# STM32F103xB register map
File version: 1.0
Registers are 32-bit, read-write, reset 0x0 unless marked. A register's access mark holds for its fields unless they carry their own. Offsets are from the block's base; [hi:lo] are bit positions; {n}, {i} and the like mark numbered series; 'fields as' and 'values as' point back to an identical list.

## BKP — Backup Registers
Base 0x40006C00
{0x0+4i} DR{i} (i=1..10)
  [15:0] D — Backup data
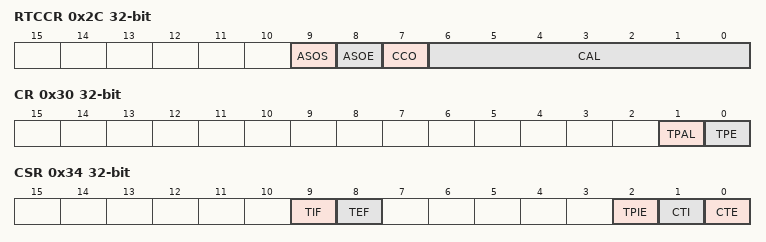
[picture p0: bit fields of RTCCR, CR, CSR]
0x2C RTCCR
  [9] ASOS — Alarm or Second Output Selection
  [8] ASOE — Alarm or Second Output Enable
  [7] CCO — Calibration Clock Output
  [6:0] CAL — Calibration value
0x30 CR
  [1] TPAL — TAMPER pin active level
    1=LOW (A high level on the TAMPER pin resets all data backup registers (if TPE bit is set)); 0=HIGH (A low level on the TAMPER pin resets all data backup registers (if TPE bit is set))
  [0] TPE — TAMPER pin enable
0x34 CSR
  [9] TIF — Tamper Interrupt Flag
  [8] TEF — Tamper Event Flag
  [2] TPIE — TAMPER Pin interrupt enable
  [1] CTI — Clear Tamper Interrupt
  [0] CTE — Clear Tamper event

## PWR — Power Control
Base 0x40007000
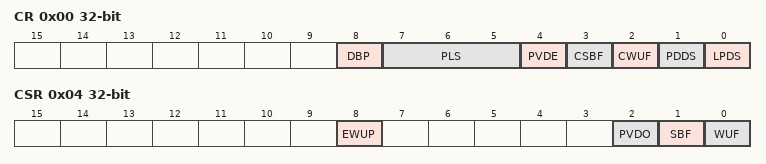
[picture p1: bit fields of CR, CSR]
0x00 CR
  [8] DBP — Disable Backup Domain write protection
  [7:5] PLS — PLS[2:0] bits (PVD Level Selection)
    0=PVDLEVEL_0 (Voltage threshold detected by PVD 2.2 V); 1=PVDLEVEL_1 (Voltage threshold detected by PVD 2.3 V); 2=PVDLEVEL_2 (Voltage threshold detected by PVD 2.4 V); 3=PVDLEVEL_3 (Voltage threshold detected by PVD 2.5 V); 4=PVDLEVEL_4 (Voltage threshold detected by PVD 2.6 V); 5=PVDLEVEL_5 (Voltage threshold detected by PVD 2.7 V); 6=PVDLEVEL_6 (Voltage threshold detected by PVD 2.8 V); 7=PVDLEVEL_7 (Voltage threshold detected by PVD 2.9 V)
  [4] PVDE — Power Voltage Detector Enable
  [3] CSBF — Clear Standby Flag
  [2] CWUF — Clear Wakeup Flag
  [1] PDDS — Power Down Deepsleep
  [0] LPDS — Low-Power Deepsleep
    0=MAIN (Voltage Regulator in main mode during deepsleep mode); 1=LOW_POWER (Voltage Regulator in low-power mode during deepsleep mode)
0x04 CSR
  [8] EWUP — Enable WKUP pin
  [2] PVDO — PVD Output
  [1] SBF — Standby Flag
  [0] WUF — Wakeup Flag

## AFIO — Alternate Function I/O
Base 0x40010000
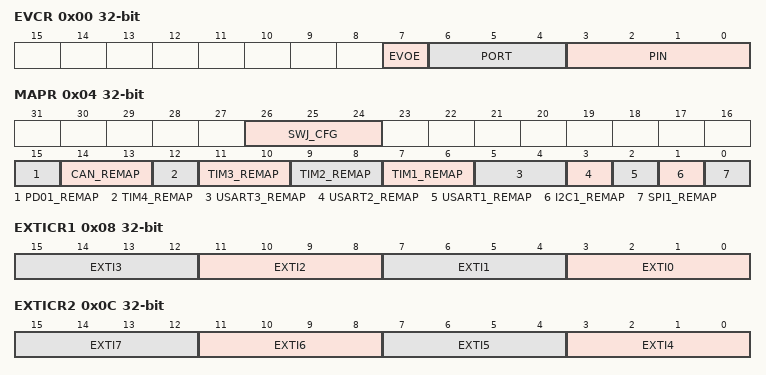
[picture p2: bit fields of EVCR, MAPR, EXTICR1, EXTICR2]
0x00 EVCR
  [7] EVOE — Event Output Enable
  [6:4] PORT — PORT[2:0] bits (Port selection)
  [3:0] PIN — PIN[3:0] bits (Pin selection)
0x04 MAPR
  [26:24] SWJ_CFG — SWJ_CFG[2:0] bits (Serial Wire JTAG configuration)
  [15] PD01_REMAP — Port D0/Port D1 mapping on OSC_IN/OSC_OUT
  [14:13] CAN_REMAP — CAN_REMAP[1:0] bits (CAN Alternate function remapping)
  [12] TIM4_REMAP — TIM4_REMAP bit (TIM4 remapping)
  [11:10] TIM3_REMAP — TIM3_REMAP[1:0] bits (TIM3 remapping)
  [9:8] TIM2_REMAP — TIM2_REMAP[1:0] bits (TIM2 remapping)
  [7:6] TIM1_REMAP — TIM1_REMAP[1:0] bits (TIM1 remapping)
  [5:4] USART3_REMAP — USART3_REMAP[1:0] bits (USART3 remapping)
  [3] USART2_REMAP — USART2 remapping
  [2] USART1_REMAP — USART1 remapping
  [1] I2C1_REMAP — I2C1 remapping
  [0] SPI1_REMAP — SPI1 remapping
0x08 EXTICR1
  [4n+3:4n] EXTI{n} (n=0..3) — EXTI {n} configuration
0x0C EXTICR2
  [4n-13:4n-16] EXTI{n} (n=4..7) — EXTI {n} configuration
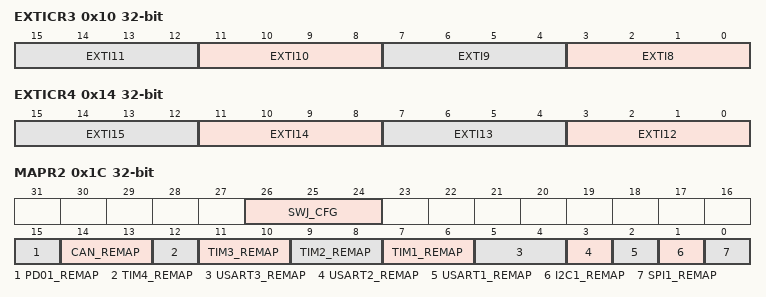
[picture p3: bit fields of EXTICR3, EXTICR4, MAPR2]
0x10 EXTICR3
  [4n-29:4n-32] EXTI{n} (n=8..11) — EXTI {n} configuration
0x14 EXTICR4
  [4n-45:4n-48] EXTI{n} (n=12..15) — EXTI {n} configuration
0x1C MAPR2
  fields as MAPR

## EXTI — External Interrupt/Event Controller
Base 0x40010400
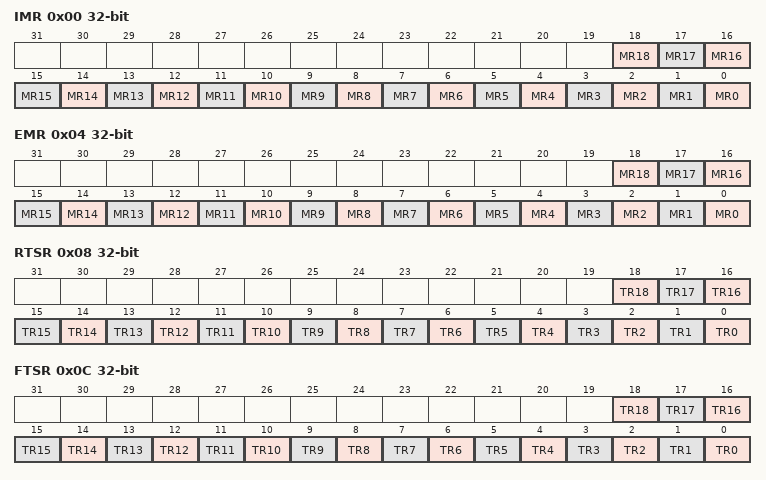
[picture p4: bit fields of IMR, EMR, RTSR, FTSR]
0x00 IMR
  [n] MR{n} (n=0..18) — Interrupt Mask on line {n}
0x04 EMR
  [n] MR{n} (n=0..18) — Event Mask on line {n}
0x08 RTSR
  [n] TR{n} (n=0..18) — Rising trigger event configuration bit of line {n}
0x0C FTSR
  [n] TR{n} (n=0..18) — Falling trigger event configuration bit of line {n}
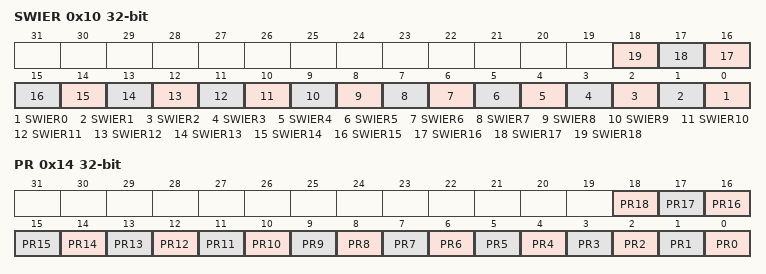
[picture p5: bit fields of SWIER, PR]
0x10 SWIER
  [n] SWIER{n} (n=0..18) — Software Interrupt on line {n}
0x14 PR
  [n] PR{n} (n=0..18) — Pending bit for line {n}

## GPIOA — General Purpose I/O
Base 0x40010800
Same registers: GPIOB 0x40010C00, GPIOC 0x40011000, GPIOD 0x40011400, GPIOE 0x40011800
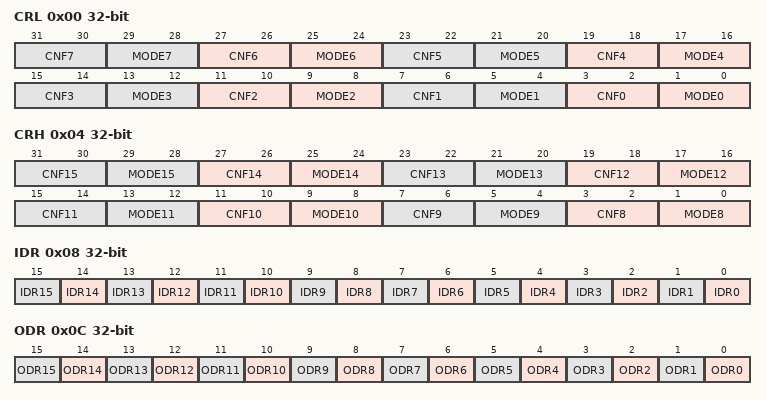
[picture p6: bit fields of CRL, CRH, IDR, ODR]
0x00 CRL
  [4n+3:4n+2] CNF{n} (n=0..7) — CNF{n}[1:0] bits (Port x configuration bits, pin {n})
  [4n+1:4n] MODE{n} (n=0..7) — MODE{n}[1:0] bits (Port x mode bits, pin {n})
0x04 CRH
  [4n-29:4n-30] CNF{n} (n=8..15) — CNF{n}[1:0] bits (Port x configuration bits, pin {n})
  [4n-31:4n-32] MODE{n} (n=8..15) — MODE{n}[1:0] bits (Port x mode bits, pin {n})
0x08 IDR
  [n] IDR{n} (n=0..15) — Port input data, bit {n}
0x0C ODR
  [n] ODR{n} (n=0..15) — Port output data, bit {n}
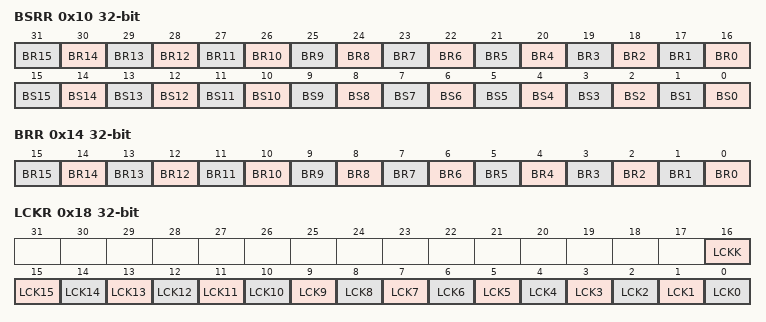
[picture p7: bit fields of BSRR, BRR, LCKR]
0x10 BSRR
  [n+16] BR{n} (n=0..15) — Port x Reset bit {n}
  [n] BS{n} (n=0..15) — Port x Set bit {n}
0x14 BRR
  [n] BR{n} (n=0..15) — Port x Reset bit {n}
0x18 LCKR
  [16] LCKK — Lock key
  [n] LCK{n} (n=0..15) — Port x Lock bit {n}
